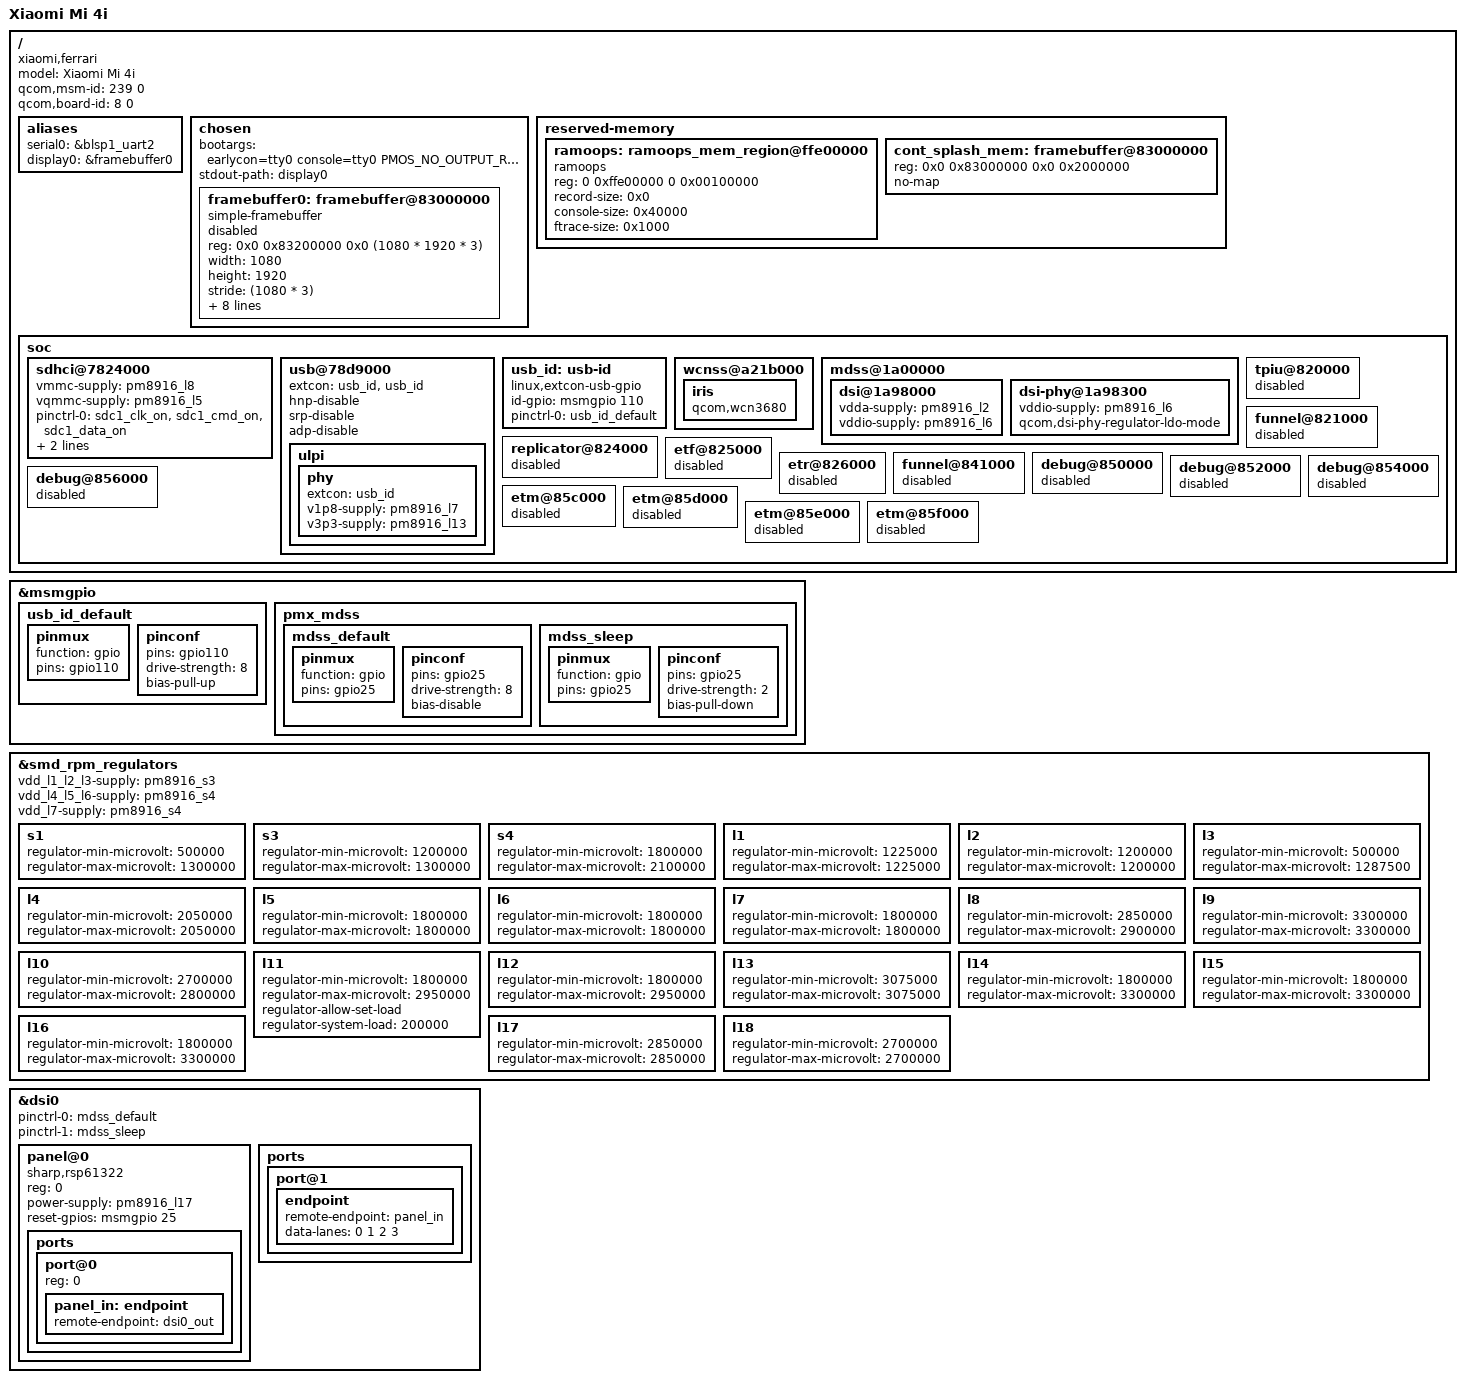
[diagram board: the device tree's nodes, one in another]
// SPDX-License-Identifier: GPL-2.0-only

/dts-v1/;

#include "msm8939.dtsi"
#include "pm8916.dtsi"
#include <dt-bindings/gpio/gpio.h>
#include <dt-bindings/input/input.h>
#include <dt-bindings/pinctrl/qcom,pmic-mpp.h>

#define DRM 1

#if DRM == 0
/ {
	/delete-node/ gpu_iommu;
	/delete-node/ gpu@1c00000;
};
#endif

/ {
	model = "Xiaomi Mi 4i";
	compatible = "xiaomi,ferrari", "qcom,msm8939-mtp", "qcom,msm8939", "qcom,mtp";
	qcom,msm-id = <239 0>;
	qcom,board-id = <8 0>;

	aliases {
		serial0 = &blsp1_uart2;
		display0 = &framebuffer0;
	};

	chosen {
	bootargs = "earlycon=tty0 console=tty0 PMOS_NO_OUTPUT_REDIRECT";
		stdout-path = "display0";

		#address-cells = <2>;
		#size-cells = <2>;
		ranges;

		framebuffer0: framebuffer@83000000 {
				status= "disabled";
				compatible = "simple-framebuffer";
				reg = <0x0 0x83200000 0x0 (1080 * 1920 * 3)>;
				width = <1080>;
				height = <1920>;
				stride = <(1080 * 3)>;
				format = "r8g8b8";
				power-domains = <&gcc MDSS_GDSC>;
				clocks = <&gcc GCC_MDSS_AHB_CLK>,
						<&gcc GCC_MDSS_VSYNC_CLK>,
						<&gcc GCC_MDSS_AXI_CLK>,
						<&gcc GCC_MDSS_MDP_CLK>,
						<&gcc GCC_MDSS_BYTE0_CLK>,
						<&gcc GCC_MDSS_PCLK0_CLK>,
						<&gcc GCC_MDSS_ESC0_CLK>,
						<&xo_board>;
		};
	};

	reserved-memory {

		#address-cells = <2>;
		#size-cells = <2>;
		ranges;

		ramoops: ramoops_mem_region@ffe00000 {
			compatible = "ramoops";
			reg = <0 0xffe00000 0 0x00100000>;

			record-size = <0x0>;
			console-size = <0x40000>;
			ftrace-size = <0x1000>;
			status = "ok";
		};

		cont_splash_mem: framebuffer@83000000 {
			reg = <0x0 0x83000000 0x0 0x2000000>; //(1080 * 1920 * 3)>;
			no-map;
		};
	};
	soc {
		sdhci@7824000 {
			status = "okay";

			vmmc-supply = <&pm8916_l8>;
			vqmmc-supply = <&pm8916_l5>;

			pinctrl-names = "default", "sleep";
			pinctrl-0 = <&sdc1_clk_on &sdc1_cmd_on &sdc1_data_on>;
			pinctrl-1 = <&sdc1_clk_off &sdc1_cmd_off &sdc1_data_off>;
		};

		//serial@78b0000 {
		//	status = "okay";
		//	pinctrl-names = "default", "sleep";
		//	pinctrl-0 = <&blsp1_uart2_default>;
		//	pinctrl-1 = <&blsp1_uart2_sleep>;
		//};

		usb@78d9000 {
			status = "okay";
			extcon = <&usb_id>, <&usb_id>;

			hnp-disable;
			srp-disable;
			adp-disable;

			ulpi {
				phy {
					extcon = <&usb_id>;
					v1p8-supply = <&pm8916_l7>;
					v3p3-supply = <&pm8916_l13>;
				};
			};
		};

		usb_id: usb-id {
			compatible = "linux,extcon-usb-gpio";
			id-gpio = <&msmgpio 110 GPIO_ACTIVE_HIGH>;
			pinctrl-names = "default";
			pinctrl-0 = <&usb_id_default>;
		};

		wcnss@a21b000 {
			status = "okay";

			iris {
				compatible = "qcom,wcn3680";
			};
		};

		mdss@1a00000 {
			status = "ok";
			dsi@1a98000 {
				#address-cells = <1>;
				#size-cells = <0>;

				vdda-supply = <&pm8916_l2>;
				vddio-supply = <&pm8916_l6>;
			};

			dsi-phy@1a98300 {
				vddio-supply = <&pm8916_l6>;
				qcom,dsi-phy-regulator-ldo-mode;
			};
		};

		/*
		 * Attempting to enable these devices causes a "synchronous
		 * external abort". Suspected cause is that the debug power
		 * domain is not enabled by default on this device.
		 * Disable these devices for now to avoid the crash.
		 *
		 * See: https://lore.kernel.org/linux-arm-msm/20190618202623.GA53651@gerhold.net/
		 */
		tpiu@820000 { status = "disabled"; };
		funnel@821000 { status = "disabled"; };
		replicator@824000 { status = "disabled"; };
		etf@825000 { status = "disabled"; };
		etr@826000 { status = "disabled"; };
		funnel@841000 { status = "disabled"; };
		debug@850000 { status = "disabled"; };
		debug@852000 { status = "disabled"; };
		debug@854000 { status = "disabled"; };
		debug@856000 { status = "disabled"; };
		etm@85c000 { status = "disabled"; };
		etm@85d000 { status = "disabled"; };
		etm@85e000 { status = "disabled"; };
		etm@85f000 { status = "disabled"; };
	};
};

&msmgpio {

	usb_id_default: usb_id_default {
                pinmux {
                        function = "gpio";
                        pins = "gpio110";
                };
                pinconf {
                        pins = "gpio110";
                        drive-strength = <8>;
                        bias-pull-up;
                };
        };

	pmx_mdss {
		mdss_default: mdss_default {
			pinmux {
				function = "gpio";
				pins = "gpio25";
			};
			pinconf {
				pins = "gpio25";
				drive-strength = <8>;
				bias-disable;
			};
		};

		mdss_sleep: mdss_sleep {
			pinmux {
				function = "gpio";
				pins = "gpio25";
			};
			pinconf {
				pins = "gpio25";
				drive-strength = <2>;
				bias-pull-down;
			};
		};
	};

};
&smd_rpm_regulators {
	vdd_l1_l2_l3-supply = <&pm8916_s3>;
	vdd_l4_l5_l6-supply = <&pm8916_s4>;
	vdd_l7-supply = <&pm8916_s4>;

	s1 {
		regulator-min-microvolt = <500000>;
		regulator-max-microvolt = <1300000>;
	};

	s3 {
		regulator-min-microvolt = <1200000>;
		regulator-max-microvolt = <1300000>;
	};

	s4 {
		regulator-min-microvolt = <1800000>;
		regulator-max-microvolt = <2100000>;
	};

	l1 {
		regulator-min-microvolt = <1225000>;
		regulator-max-microvolt = <1225000>;
	};

	l2 {
		regulator-min-microvolt = <1200000>;
		regulator-max-microvolt = <1200000>;
	};

	l3 {
		regulator-min-microvolt = <500000>;
		regulator-max-microvolt = <1287500>;
	};

	l4 {
		regulator-min-microvolt = <2050000>;
		regulator-max-microvolt = <2050000>;
	};

	l5 {
		regulator-min-microvolt = <1800000>;
		regulator-max-microvolt = <1800000>;
	};

	l6 {
		regulator-min-microvolt = <1800000>;
		regulator-max-microvolt = <1800000>;
	};

	l7 {
		regulator-min-microvolt = <1800000>;
		regulator-max-microvolt = <1800000>;
	};

	l8 {
		regulator-min-microvolt = <2850000>;
		regulator-max-microvolt = <2900000>;
	};

	l9 {
		regulator-min-microvolt = <3300000>;
		regulator-max-microvolt = <3300000>;
	};

	l10 {
		regulator-min-microvolt = <2700000>;
		regulator-max-microvolt = <2800000>;
	};

	l11 {
		regulator-min-microvolt = <1800000>;
		regulator-max-microvolt = <2950000>;
		regulator-allow-set-load;
		regulator-system-load = <200000>;
	};

	l12 {
		regulator-min-microvolt = <1800000>;
		regulator-max-microvolt = <2950000>;
	};

	l13 {
		regulator-min-microvolt = <3075000>;
		regulator-max-microvolt = <3075000>;
	};

	l14 {
		regulator-min-microvolt = <1800000>;
		regulator-max-microvolt = <3300000>;
	};

	l15 {
		regulator-min-microvolt = <1800000>;
		regulator-max-microvolt = <3300000>;
	};

	l16 {
		regulator-min-microvolt = <1800000>;
		regulator-max-microvolt = <3300000>;
	};

	l17 {
		regulator-min-microvolt = <2850000>;
		regulator-max-microvolt = <2850000>;
	};

	l18 {
		regulator-min-microvolt = <2700000>;
		regulator-max-microvolt = <2700000>;
	};
};

#if DRM
&dsi0 {
	pinctrl-names = "default", "sleep";
	pinctrl-0 = <&mdss_default>;
	pinctrl-1 = <&mdss_sleep>;

	panel@0 {
		compatible = "sharp,rsp61322";
		reg = <0>;

		power-supply = <&pm8916_l17>;
		reset-gpios = <&msmgpio 25 GPIO_ACTIVE_HIGH>;

		ports {
			#address-cells = <1>;
			#size-cells = <0>;

			port@0 {
				reg = <0>;
				panel_in: endpoint {
					remote-endpoint = <&dsi0_out>;
				};
			};
		};
	};

	ports {
		port@1 {
			endpoint {
				remote-endpoint = <&panel_in>;
				data-lanes = <0 1 2 3>;
			};
		};
	};
};
#endif // DRM
